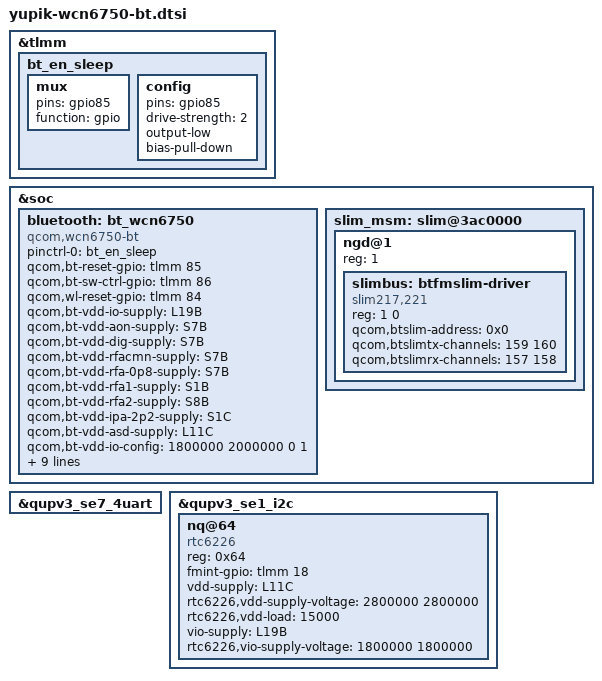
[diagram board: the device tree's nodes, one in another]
// SPDX-License-Identifier: BSD-3-Clause

/*
 * Copyright (c) Qualcomm Technologies, Inc. and/or its subsidiaries.
 */

#include <dt-bindings/interrupt-controller/arm-gic.h>
#include <dt-bindings/gpio/gpio.h>
#include <dt-bindings/interconnect/qcom,yupik.h>

&tlmm {
	bt_en_sleep: bt_en_sleep {
		mux {
			pins = "gpio85";
			function = "gpio";
		};

		config {
			pins = "gpio85";
			drive-strength = <2>;
			output-low;
			bias-pull-down;
		};
	};
};

&soc {
	bluetooth: bt_wcn6750 {
		compatible = "qcom,wcn6750-bt";
		pinctrl-names = "default";
		pinctrl-0 = <&bt_en_sleep>;
		qcom,bt-reset-gpio = <&tlmm 85 0>; /* BT_EN */
		qcom,bt-sw-ctrl-gpio = <&tlmm 86 0>; /* SW_CTRL */
		qcom,wl-reset-gpio = <&tlmm 84 0>; /* WL_EN */

		qcom,bt-vdd-io-supply = <&L19B>;  /* IO */
		qcom,bt-vdd-aon-supply = <&S7B>;
		qcom,bt-vdd-dig-supply = <&S7B>;
		qcom,bt-vdd-rfacmn-supply = <&S7B>;
		qcom,bt-vdd-rfa-0p8-supply = <&S7B>;
		qcom,bt-vdd-rfa1-supply = <&S1B>; /*RFA 1p7*/
		qcom,bt-vdd-rfa2-supply = <&S8B>; /*RFA 1p2*/
		qcom,bt-vdd-ipa-2p2-supply = <&S1C>; /*IPA 2p2*/
		qcom,bt-vdd-asd-supply = <&L11C>;

		/* max voltage are set to regulator max voltage supported */
		qcom,bt-vdd-io-config = <1800000 2000000 0 1>;
		qcom,bt-vdd-aon-config = <824000 1120000 0 1>;
		qcom,bt-vdd-dig-config = <824000 1120000 0 1>;
		qcom,bt-vdd-rfacmn-config  = <824000 1120000 0 1>;
		qcom,bt-vdd-rfa-0p8-config  = <824000 1120000 0 1>;
		qcom,bt-vdd-rfa1-config = <1872000 2040000 0 1>;
		qcom,bt-vdd-rfa2-config = <1256000 1500000 0 1>;
		qcom,bt-vdd-ipa-2p2-config = <2200000 2210000 0 1>;
		qcom,bt-vdd-asd-config = <2800000 3544000 0 1>;
	};
	slim_msm: slim@3ac0000 {
		status =  "ok";
		ngd@1 {
			reg = <1>;
			#address-cells = <1>;
			#size-cells = <1>;
			//slimbus child nodes
			slimbus: btfmslim-driver {
				compatible = "slim217,221";
				reg = <1 0>;
				qcom,btslim-address  = <0x0>;
				qcom,btslimtx-channels = <159 160>;
				qcom,btslimrx-channels = <157 158>;
			};
		};
   };
};

//uart instance
&qupv3_se7_4uart {
	status = "ok";
};

&qupv3_se1_i2c {
	status = "ok";
	nq@64 {
		compatible = "rtc6226";
		reg = <0x64>;
		fmint-gpio = <&tlmm 18 0>;
		vdd-supply = <&L11C>;
		rtc6226,vdd-supply-voltage = <2800000 2800000>;
		rtc6226,vdd-load = <15000>;
		vio-supply = <&L19B>;
		rtc6226,vio-supply-voltage = <1800000 1800000>;
	};
};
